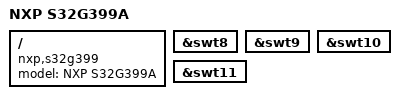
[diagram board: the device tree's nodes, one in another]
// SPDX-License-Identifier: GPL-2.0-or-later
/*
 * Copyright 2022 NXP
 */

/dts-v1/;
#include "fsl-s32g3.dtsi"
#include "fsl-s32gxxxa-evb.dtsi"
/ {
	model = "NXP S32G399A";
	compatible = "nxp,s32g399";
};

&swt8 {
	status = "okay";
};

&swt9 {
	status = "okay";
};

&swt10 {
	status = "okay";
};

&swt11 {
	status = "okay";
};
